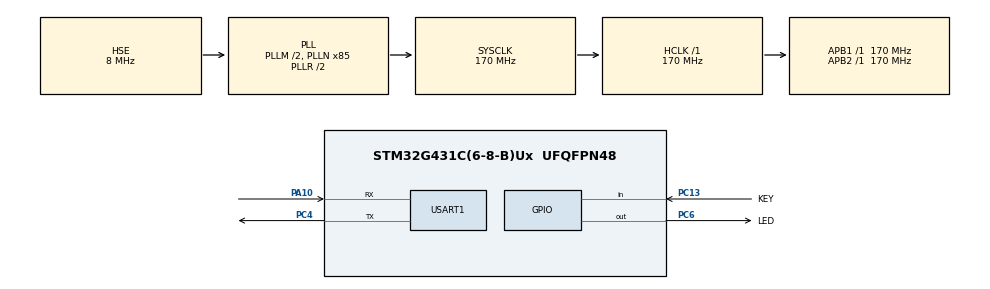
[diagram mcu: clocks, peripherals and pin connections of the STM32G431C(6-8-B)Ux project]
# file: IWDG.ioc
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IWDG.Prescaler=IWDG_PRESCALER_16
IWDG.Reload=2000
IWDG.Window=4095
Mcu.Family=STM32G4
Mcu.Name=STM32G431C(6-8-B)Ux
Mcu.Package=UFQFPN48
NVIC.PriorityGroup=NVIC_PRIORITYGROUP_4
PA10.Mode=Asynchronous
PA10.Signal=USART1_RX
PA13.Mode=Trace_Asynchronous_SW
PA13.Signal=SYS_JTMS-SWDIO
PA14.Mode=Trace_Asynchronous_SW
PA14.Signal=SYS_JTCK-SWCLK
PB3.Mode=Trace_Asynchronous_SW
PB3.Signal=SYS_JTDO-SWO
PC13.GPIO_Label=KEY
PC13.GPIO_PuPd=GPIO_PULLDOWN
PC13.Signal=GPIO_Input
PC4.Mode=Asynchronous
PC4.Signal=USART1_TX
PC6.GPIO_Label=LED
PC6.GPIO_ModeDefaultOutputPP=GPIO_MODE_OUTPUT_PP
PC6.GPIO_Speed=GPIO_SPEED_FREQ_LOW
PC6.PinState=GPIO_PIN_RESET
PC6.Signal=GPIO_Output
PF0-OSC_IN.Mode=HSE-External-Oscillator
PF0-OSC_IN.Signal=RCC_OSC_IN
PF1-OSC_OUT.Mode=HSE-External-Oscillator
PF1-OSC_OUT.Signal=RCC_OSC_OUT
ProjectManager.HeapSize=0x200
ProjectManager.StackSize=0x400
ProjectManager.TargetToolchain=STM32CubeIDE
RCC.ADC12Freq_Value=170000000
RCC.AHBFreq_Value=170000000
RCC.APB1Freq_Value=170000000
RCC.APB1TimFreq_Value=170000000
RCC.APB2Freq_Value=170000000
RCC.APB2TimFreq_Value=170000000
RCC.CortexFreq_Value=170000000
RCC.EXTERNAL_CLOCK_VALUE=12288000
RCC.HCLKFreq_Value=170000000
RCC.HSE_VALUE=8000000
RCC.HSI48_VALUE=48000000
RCC.HSI_VALUE=16000000
RCC.LSE_VALUE=32768
RCC.PLLM=RCC_PLLM_DIV2
RCC.PLLN=85
RCC.PLLSourceVirtual=RCC_PLLSOURCE_HSE
RCC.SYSCLKFreq_VALUE=170000000
RCC.SYSCLKSource=RCC_SYSCLKSOURCE_PLLCLK
RCC.USBFreq_Value=170000000
RCC.VCOOutputFreq_Value=340000000
USART1.VirtualMode-Asynchronous=VM_ASYNC
VP_IWDG_VS_IWDG.Mode=IWDG_Activate
VP_SYS_VS_DBSignals.Mode=DisableDeadBatterySignals
board=custom

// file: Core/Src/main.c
/* USER CODE BEGIN Header */
/**
  ******************************************************************************
  * @file           : main.c
  * @brief          : Main program body
  ******************************************************************************
  * @attention
  *
  * Copyright (c) 2025 STMicroelectronics.
  * All rights reserved.
  *
  * This software is licensed under terms that can be found in the LICENSE file
  * in the root directory of this software component.
  * If no LICENSE file comes with this software, it is provided AS-IS.
  *
  ******************************************************************************
  */
/* USER CODE END Header */
#include "main.h"

/* USER CODE BEGIN Includes */

#include <stdio.h>
#include "reset_cause.h"

/* USER CODE END Includes */

IWDG_HandleTypeDef hiwdg;

UART_HandleTypeDef huart1;

void SystemClock_Config(void);
static void MX_GPIO_Init(void);
static void MX_IWDG_Init(void);
static void MX_USART1_UART_Init(void);

int main(void)
{

  /* MCU Configuration--------------------------------------------------------*/

  /* Reset of all peripherals, Initializes the Flash interface and the Systick. */
  HAL_Init();

  /* Configure the system clock */
  SystemClock_Config();

  /* Initialize all configured peripherals */
  MX_GPIO_Init();
  MX_IWDG_Init();
  MX_USART1_UART_Init();
  /* USER CODE BEGIN 2 */

  reset_cause_t reset_cause = reset_cause_get();
  printf("\r\nThe system reset cause is \"%s\"\n", reset_cause_get_name(reset_cause));

  /* USER CODE END 2 */

  /* Infinite loop */
  /* USER CODE BEGIN WHILE */
  while (1)
  {
	  HAL_Delay(450);
	  HAL_GPIO_TogglePin(LED_GPIO_Port, LED_Pin);

	  /*
	   * hiwdg.Init.Reload calculation:  Reload = (Period sec * CLC)/Prescaler
	   * for examle: Period sec = 1sec  Reload = (1 * 32000)/16 = 2000
	   * if hiwdg.Init.Window = 4095; Its means the Window not used
	   *
	   * Example without using Window: HAL_Delay(); from 1 to 950 - OK; more then 1000 - rebooting
	   *
	   * When hiwdg.Init.Window = 1000; Its means the IWD must be reset before it counts to 1, but not before it counts to 1000
	   *
	   ** Example with using Window = 1000; HAL_Delay(); from 550 to 950 - OK; more then 1000 - rebooting, less then 500 - rebooting
	   **
	   */
	  // Reset Watchdog
	  HAL_IWDG_Refresh(&hiwdg);

    /* USER CODE END WHILE */

  }
}

void SystemClock_Config(void)
{
  RCC_OscInitTypeDef RCC_OscInitStruct = {0};
  RCC_ClkInitTypeDef RCC_ClkInitStruct = {0};

  /** Configure the main internal regulator output voltage
  */
  HAL_PWREx_ControlVoltageScaling(PWR_REGULATOR_VOLTAGE_SCALE1_BOOST);

  /** Initializes the RCC Oscillators according to the specified parameters
  * in the RCC_OscInitTypeDef structure.
  */
  RCC_OscInitStruct.OscillatorType = RCC_OSCILLATORTYPE_LSI|RCC_OSCILLATORTYPE_HSE;
  RCC_OscInitStruct.HSEState = RCC_HSE_ON;
  RCC_OscInitStruct.LSIState = RCC_LSI_ON;
  RCC_OscInitStruct.PLL.PLLState = RCC_PLL_ON;
  RCC_OscInitStruct.PLL.PLLSource = RCC_PLLSOURCE_HSE;
  RCC_OscInitStruct.PLL.PLLM = RCC_PLLM_DIV2;
  RCC_OscInitStruct.PLL.PLLN = 85;
  RCC_OscInitStruct.PLL.PLLP = RCC_PLLP_DIV2;
  RCC_OscInitStruct.PLL.PLLQ = RCC_PLLQ_DIV2;
  RCC_OscInitStruct.PLL.PLLR = RCC_PLLR_DIV2;
  if (HAL_RCC_OscConfig(&RCC_OscInitStruct) != HAL_OK)
  {
    Error_Handler();
  }

  /** Initializes the CPU, AHB and APB buses clocks
  */
  RCC_ClkInitStruct.ClockType = RCC_CLOCKTYPE_HCLK|RCC_CLOCKTYPE_SYSCLK
                              |RCC_CLOCKTYPE_PCLK1|RCC_CLOCKTYPE_PCLK2;
  RCC_ClkInitStruct.SYSCLKSource = RCC_SYSCLKSOURCE_PLLCLK;
  RCC_ClkInitStruct.AHBCLKDivider = RCC_SYSCLK_DIV1;
  RCC_ClkInitStruct.APB1CLKDivider = RCC_HCLK_DIV1;
  RCC_ClkInitStruct.APB2CLKDivider = RCC_HCLK_DIV1;

  if (HAL_RCC_ClockConfig(&RCC_ClkInitStruct, FLASH_LATENCY_4) != HAL_OK)
  {
    Error_Handler();
  }
}

static void MX_IWDG_Init(void)
{

  hiwdg.Instance = IWDG;
  hiwdg.Init.Prescaler = IWDG_PRESCALER_16;
  hiwdg.Init.Window = 4095;
  hiwdg.Init.Reload = 2000;
  if (HAL_IWDG_Init(&hiwdg) != HAL_OK)
  {
    Error_Handler();
  }

}

static void MX_USART1_UART_Init(void)
{

  huart1.Instance = USART1;
  huart1.Init.BaudRate = 115200;
  huart1.Init.WordLength = UART_WORDLENGTH_8B;
  huart1.Init.StopBits = UART_STOPBITS_1;
  huart1.Init.Parity = UART_PARITY_NONE;
  huart1.Init.Mode = UART_MODE_TX_RX;
  huart1.Init.HwFlowCtl = UART_HWCONTROL_NONE;
  huart1.Init.OverSampling = UART_OVERSAMPLING_16;
  huart1.Init.OneBitSampling = UART_ONE_BIT_SAMPLE_DISABLE;
  huart1.Init.ClockPrescaler = UART_PRESCALER_DIV1;
  huart1.AdvancedInit.AdvFeatureInit = UART_ADVFEATURE_NO_INIT;
  if (HAL_UART_Init(&huart1) != HAL_OK)
  {
    Error_Handler();
  }
  if (HAL_UARTEx_SetTxFifoThreshold(&huart1, UART_TXFIFO_THRESHOLD_1_8) != HAL_OK)
  {
    Error_Handler();
  }
  if (HAL_UARTEx_SetRxFifoThreshold(&huart1, UART_RXFIFO_THRESHOLD_1_8) != HAL_OK)
  {
    Error_Handler();
  }
  if (HAL_UARTEx_DisableFifoMode(&huart1) != HAL_OK)
  {
    Error_Handler();
  }

}

static void MX_GPIO_Init(void)
{
  GPIO_InitTypeDef GPIO_InitStruct = {0};

  /* GPIO Ports Clock Enable */
  __HAL_RCC_GPIOC_CLK_ENABLE();
  __HAL_RCC_GPIOF_CLK_ENABLE();
  __HAL_RCC_GPIOA_CLK_ENABLE();
  __HAL_RCC_GPIOB_CLK_ENABLE();

  /*Configure GPIO pin Output Level */
  HAL_GPIO_WritePin(LED_GPIO_Port, LED_Pin, GPIO_PIN_RESET);

  /*Configure GPIO pin : KEY_Pin */
  GPIO_InitStruct.Pin = KEY_Pin;
  GPIO_InitStruct.Mode = GPIO_MODE_INPUT;
  GPIO_InitStruct.Pull = GPIO_PULLDOWN;
  HAL_GPIO_Init(KEY_GPIO_Port, &GPIO_InitStruct);

  /*Configure GPIO pin : LED_Pin */
  GPIO_InitStruct.Pin = LED_Pin;
  GPIO_InitStruct.Mode = GPIO_MODE_OUTPUT_PP;
  GPIO_InitStruct.Pull = GPIO_NOPULL;
  GPIO_InitStruct.Speed = GPIO_SPEED_FREQ_LOW;
  HAL_GPIO_Init(LED_GPIO_Port, &GPIO_InitStruct);

}

void Error_Handler(void)
{
  __disable_irq();
  while (1)
  {
  }
}
